# ISP6P5_NSF3V register map
Vendor: Texas Instruments
Peripheral module from a debugger description file (folder DRA74xP_75xP_76xP_77xP).
Registers are 32-bit, access per field, reset 0x0 unless marked. A register's access mark holds for its fields unless they carry their own. Offsets are as the file gives them; lines under a group give offsets from that group; [hi:lo] are bit positions; {n}, {i} and the like mark numbered series; 'fields as' and 'values as' point back to an identical list; <NAME> marks a mode.

## ISP6P5_NSF3V
0x00 NSF3V_SYSCONFIG — OCP interface
  [0] SOFTRESET rw — Software reset Read 0: Reset done, no pending action Write 0: No action Write 1: Initiate software reset Read 1: Reset (software or other) ongoing
0x08 NSF3V_CTRL — Control
  [0] EN rw — Enable NSF3V operation, for either single frame or video, depending onNSF3V_CFG.ONESHOT. Writing 0 stops NSF3V operation and puts it in idle mode.
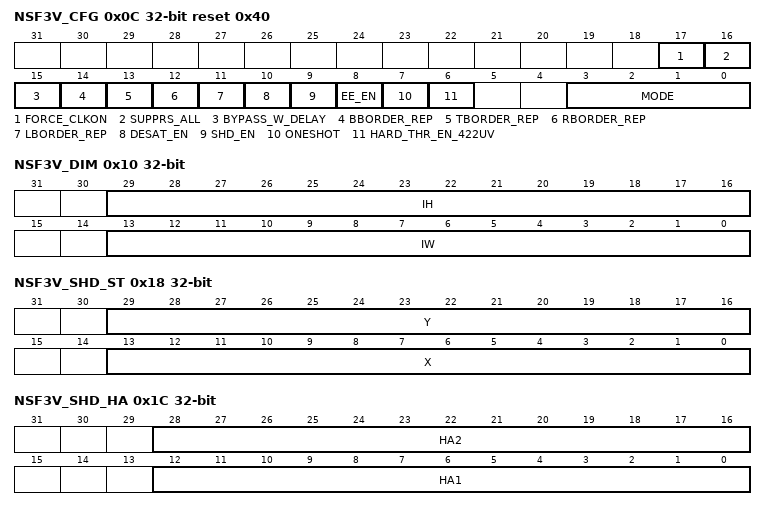
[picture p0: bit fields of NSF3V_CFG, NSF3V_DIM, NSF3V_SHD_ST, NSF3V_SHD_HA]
0x0C NSF3V_CFG reset 0x40 — Configuration
  [17] FORCE_CLKON rw — Force clock to be on, disabling clock autogating.
  [16] SUPPRS_ALL rw — Suppress all subband signals (debug mode). In normal operation, this should be set 0.
  [15] BYPASS_W_DELAY rw — Bypass all processing, so that output = input, but maintain the same latency
  [14] BBORDER_REP rw — Replicate top border to not lose 7 lines per color on the bottom.
  [13] TBORDER_REP rw — Replicate top border to not lose 7 lines per color on the top.
  [12] RBORDER_REP rw — Replicate right border to not lose 8 data points per color on the right.
  [11] LBORDER_REP rw — Replicate left border to not lose 8 data points per color on the left.
  [10] DESAT_EN rw — enable chroma desaturation
  [9] SHD_EN rw — enable shading gain
  [8] EE_EN rw — enable edge enhancement
  [7] ONESHOT rw — Video (continuous operation) or one shot (single-frame): 0 = video 1 = one-shot
  [6] HARD_THR_EN_422UV rw — Hard thresholding enable, applicable to YUV422 (normal and interleaved) UV path
  [3:0] MODE rw — Mode of operation: 0 = Bayer 1 = Bayer interleaved 2x2 2 = Bayer interleaved 3x3 3 = YUV422 4 = YUV420 Y plane 5 = YuV420 UV plane 6 = YUV422 interleaved 7 = YUV420 Y interleaved 8 = YUV420 UV interleaved 9 ~ 15 = reserved
0x10 NSF3V_DIM — Image block dimension
  [29:16] IH rw — Image height, in lines. For Bayer, YUV422, and YUV420_Y, this is same as vertical resolution in pixels. For YUV420_UV, image height is half of vertical resolution in pixels.
  [13:0] IW rw — Image width, in pixels. For Bayer and YUV420_Y, YUV420_UV, this is the same as number of data points horizontally. For YUV422, this is half of number of data points horizontally.
0x14 NSF3V_VPOUT_CTRL reset 0xFFFF — Video port output control
  [15:0] PCLK rw — Video port output data rate, indicate that VPOUT EN signal should be sent functional clock * PCLK / 65536. Must be 0, = 65535
0x18 NSF3V_SHD_ST — Shading gain starting coordinate
  [29:16] Y rw — shading gain starting Y coordinate
  [13:0] X rw — shading gain starting X coordinate
0x1C NSF3V_SHD_HA — Shading gain HA1/HA2
  [28:16] HA2 rw — shading gain HA2 coefficient
  [12:0] HA1 rw — shading gain HA1 coefficient
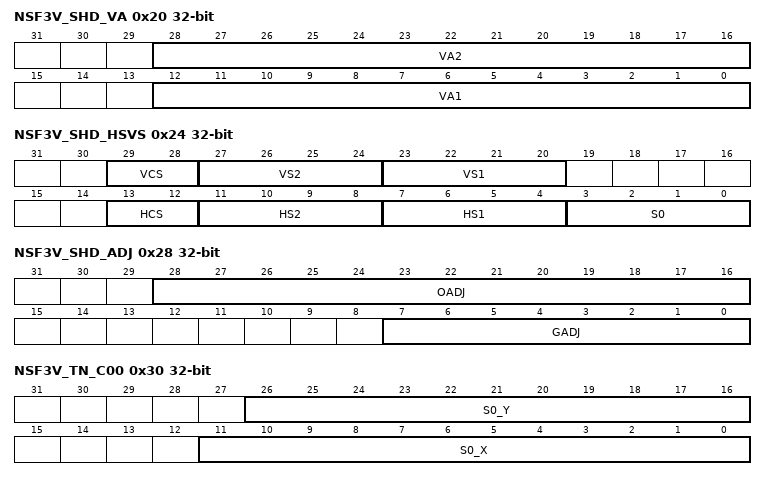
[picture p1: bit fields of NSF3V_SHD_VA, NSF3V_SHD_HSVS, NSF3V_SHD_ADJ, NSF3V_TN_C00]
0x20 NSF3V_SHD_VA — Shading gain VA1/VA2
  [28:16] VA2 rw — shading gain VA2 coefficient
  [12:0] VA1 rw — shading gain VA1 coefficient
0x24 NSF3V_SHD_HSVS — Shading gain shift counts
  [29:28] VCS rw — Vshading gain VCS shift count, only 1 or 2 allowed
  [27:24] VS2 rw — shading gain VS2 shift count
  [23:20] VS1 rw — shading gain VS1 bit count
  [13:12] HCS rw — shading gain HCS shift count, only 1 or 2 allowed
  [11:8] HS2 rw — shading gain HS2 bit count
  [7:4] HS1 rw — shading gain HS1 shift count
  [3:0] S0 rw — shading gain S0 shift count
0x28 NSF3V_SHD_ADJ — Shading gain adjustment
  [28:16] OADJ rw — shading gain offset adjustment
  [7:0] GADJ rw — shading gain gain adjustment, unsigned
0x2C NSF3V_SHD_MAXG — Max shading gain
  [8:0] MAXG rw
0x30 NSF3V_TN_C00 — Color 0 noise threshold
  [26:16] S0_Y rw — segment 0 Y coordinate, U11
  [11:0] S0_X ro — segment 0 X coordinate, U12, fixed to 0 (read-only)
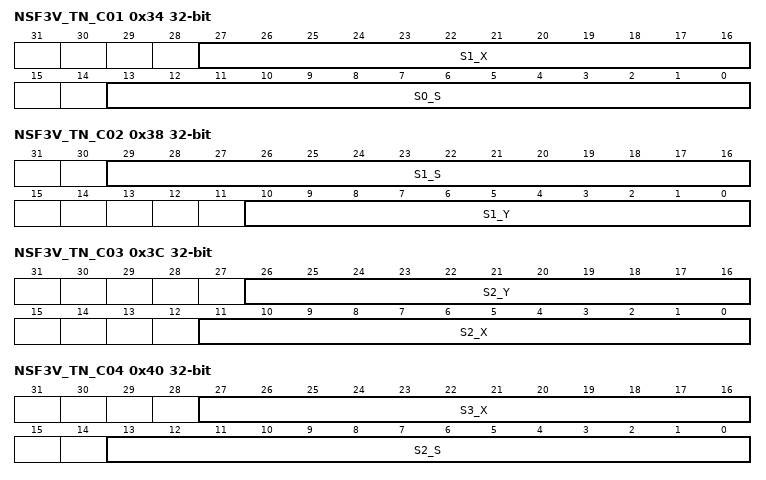
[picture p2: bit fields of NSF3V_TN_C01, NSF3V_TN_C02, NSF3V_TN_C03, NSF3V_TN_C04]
0x34 NSF3V_TN_C01 — Color 0 noise threshold
  [27:16] S1_X rw — segment 1 X coordinate, U12
  [13:0] S0_S rw — segment 0 slope, S3.11
0x38 NSF3V_TN_C02 — Color 0 noise threshold
  [29:16] S1_S rw — segment 1 slope, S3.11
  [10:0] S1_Y rw — segment 1 Y coordinate, U11
0x3C NSF3V_TN_C03 — Color 0 noise threshold
  [26:16] S2_Y rw — segment 2 Y coordinate, U11
  [11:0] S2_X rw — segment 2 X coordinate, U12
0x40 NSF3V_TN_C04 — Color 0 noise threshold
  [27:16] S3_X rw — segment 3 X coordinate, U12
  [13:0] S2_S rw — segment 2 slope, S3.11
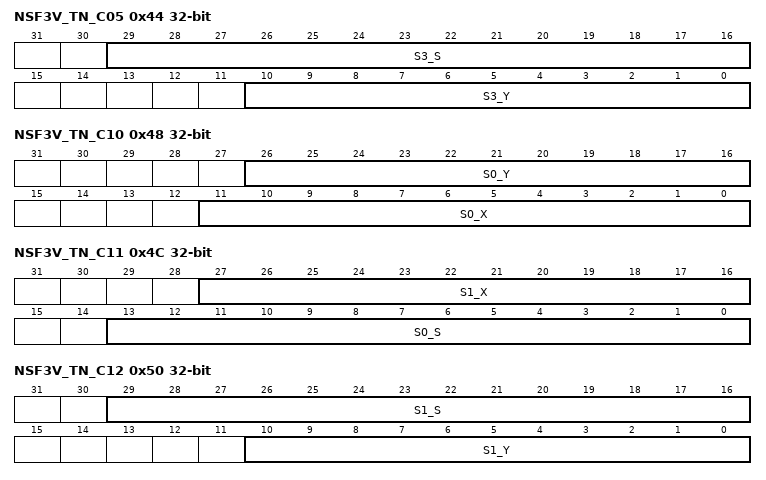
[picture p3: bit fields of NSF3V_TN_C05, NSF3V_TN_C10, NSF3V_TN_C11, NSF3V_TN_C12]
0x44 NSF3V_TN_C05 — Color 0 noise threshold
  [29:16] S3_S rw — segment 3 slope, S3.11
  [10:0] S3_Y rw — segment 3 Y coordinate, U11
0x48 NSF3V_TN_C10 — Color 1 noise threshold
  fields as NSF3V_TN_C00
0x4C NSF3V_TN_C11 — Color 1 noise threshold
  fields as NSF3V_TN_C01
0x50 NSF3V_TN_C12 — Color 1 noise threshold
  fields as NSF3V_TN_C02
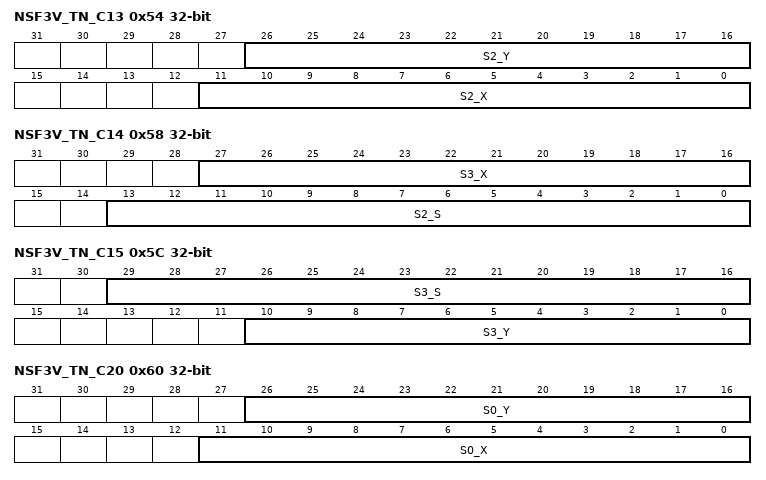
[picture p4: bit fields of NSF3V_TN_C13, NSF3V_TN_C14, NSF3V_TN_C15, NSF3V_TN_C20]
0x54 NSF3V_TN_C13 — Color 1 noise threshold
  fields as NSF3V_TN_C03
0x58 NSF3V_TN_C14 — Color 1 noise threshold
  fields as NSF3V_TN_C04
0x5C NSF3V_TN_C15 — Color 1 noise threshold
  fields as NSF3V_TN_C05
0x60 NSF3V_TN_C20 — Color 2 noise threshold
  fields as NSF3V_TN_C00
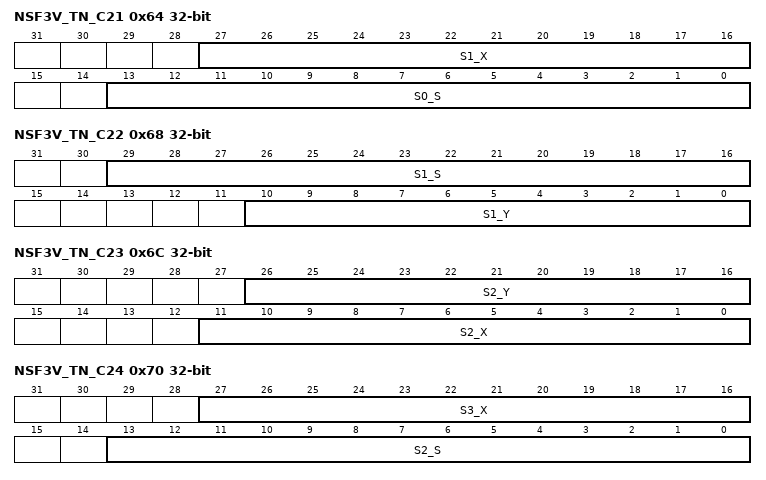
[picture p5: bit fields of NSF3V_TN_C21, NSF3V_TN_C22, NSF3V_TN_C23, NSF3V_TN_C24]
0x64 NSF3V_TN_C21 — Color 2 noise threshold
  fields as NSF3V_TN_C01
0x68 NSF3V_TN_C22 — Color 2 noise threshold
  fields as NSF3V_TN_C02
0x6C NSF3V_TN_C23 — Color 2 noise threshold
  fields as NSF3V_TN_C03
0x70 NSF3V_TN_C24 — Color 2 noise threshold
  fields as NSF3V_TN_C04
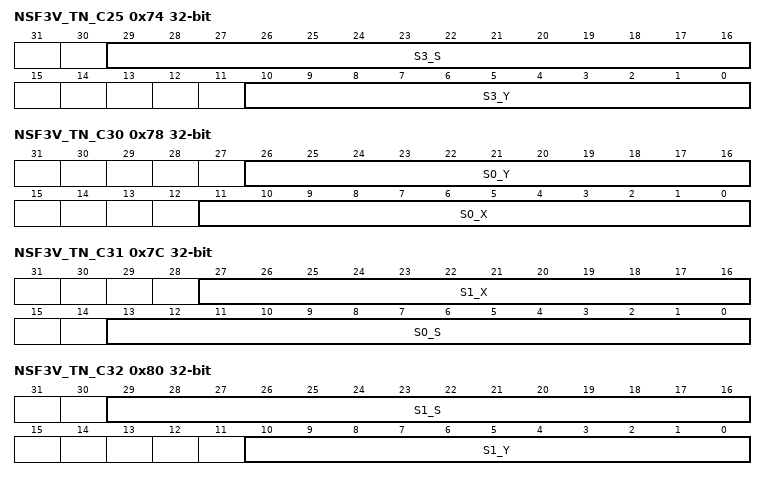
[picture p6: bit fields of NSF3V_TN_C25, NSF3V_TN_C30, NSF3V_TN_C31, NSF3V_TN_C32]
0x74 NSF3V_TN_C25 — Color 2 noise threshold
  fields as NSF3V_TN_C05
0x78 NSF3V_TN_C30 — Color 3 noise threshold
  fields as NSF3V_TN_C00
0x7C NSF3V_TN_C31 — Color 3 noise threshold
  fields as NSF3V_TN_C01
0x80 NSF3V_TN_C32 — Color 3 noise threshold
  fields as NSF3V_TN_C02
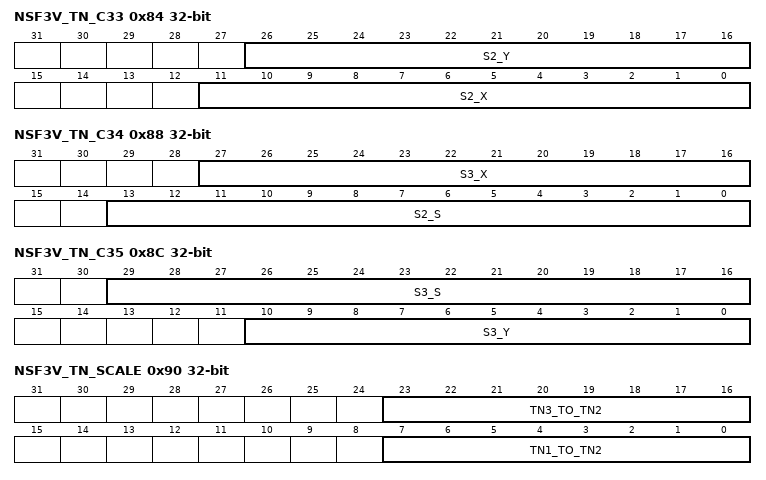
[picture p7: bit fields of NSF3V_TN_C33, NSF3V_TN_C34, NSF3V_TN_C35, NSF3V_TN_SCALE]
0x84 NSF3V_TN_C33 — Color 3 noise threshold
  fields as NSF3V_TN_C03
0x88 NSF3V_TN_C34 — Color 3 noise threshold
  fields as NSF3V_TN_C04
0x8C NSF3V_TN_C35 — Color 3 noise threshold
  fields as NSF3V_TN_C05
0x90 NSF3V_TN_SCALE
  [23:16] TN3_TO_TN2 rw — Scaling factor to get TN3, noise threshold for level 3 subbands, U3.5.
  [7:0] TN1_TO_TN2 rw — Scaling factor to get TN1, noise threshold for level 1 subbands, U3.5.
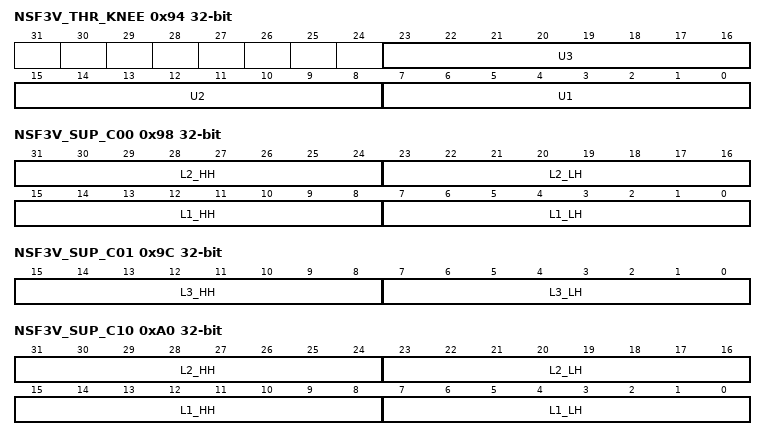
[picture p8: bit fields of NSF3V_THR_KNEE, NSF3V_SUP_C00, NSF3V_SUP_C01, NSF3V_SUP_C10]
0x94 NSF3V_THR_KNEE — Thresholding knee points
  [23:16] U3 rw — Knee point u3, above which ee = ee_max. U2.6 representation, 64 = u2 u3 = 255.
  [15:8] U2 rw — Knee point u2, below which ee = 0. Above u2, ee increases linearly to ee_max at u = u3. U2.6 representation, 64 = u2 u3 = 255.
  [7:0] U1 rw — Knee point u1, below which suppression = suppression_max. Above u1, suppression decreases linearly to 0 at u = 1.0. U2.6 representation, between 0 and 63.
0x98 NSF3V_SUP_C00 rw — Color 0 suppression max
  [31:24] L2_HH — Level 2 HH subband suppression_max, U1.7.
  [23:16] L2_LH — Level 2 LH and HL subband suppression_max, U1.7.
  [15:8] L1_HH — Level 1 HH subband suppression_max, U1.7.
  [7:0] L1_LH — Level 1 LH and HL subband suppression_max, U1.7.
0x9C NSF3V_SUP_C01 — Color 0 suppression max
  [15:8] L3_HH rw — Level 3 HH subband suppression_max, U1.7.
  [7:0] L3_LH rw — Level 3 LH and HL subband suppression_max, U1.7.
0xA0 NSF3V_SUP_C10 rw — Color 1 suppression max
  fields as NSF3V_SUP_C00
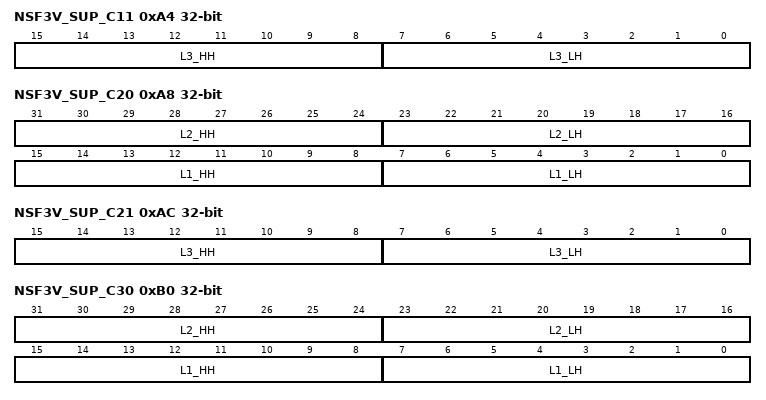
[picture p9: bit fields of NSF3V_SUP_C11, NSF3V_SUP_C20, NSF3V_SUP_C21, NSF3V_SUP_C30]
0xA4 NSF3V_SUP_C11 — Color 1 suppression max
  fields as NSF3V_SUP_C01
0xA8 NSF3V_SUP_C20 rw — Color 2 suppression max
  fields as NSF3V_SUP_C00
0xAC NSF3V_SUP_C21 — Color 2 suppression max
  fields as NSF3V_SUP_C01
0xB0 NSF3V_SUP_C30 rw — Color 3 suppression max
  fields as NSF3V_SUP_C00
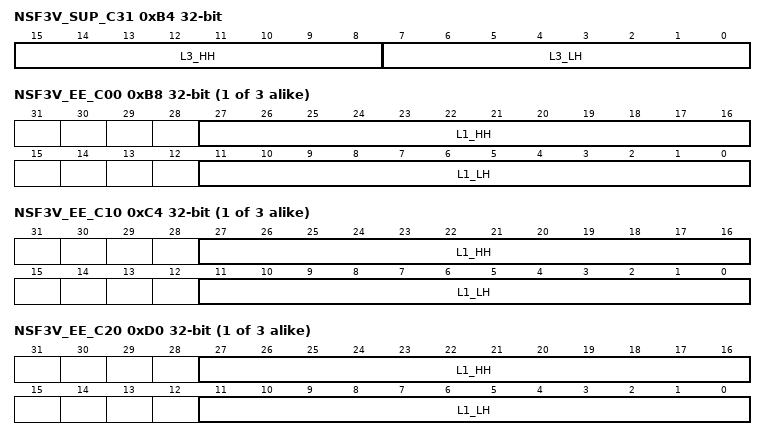
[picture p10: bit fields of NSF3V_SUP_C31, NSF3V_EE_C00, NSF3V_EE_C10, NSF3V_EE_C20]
0xB4 NSF3V_SUP_C31 — Color 3 suppression max
  fields as NSF3V_SUP_C01
{0xB8+4i} NSF3V_EE_C{i:02} (i=0..2) — Color 0 edge enhancement max
  [27:16] L{i+1}_HH rw — Level {i+1} HH suband ee_max, U10.2
  [11:0] L{i+1}_LH rw — Level {i+1} LH and HL subband ee_max, U10.2
{0x9C+4i} NSF3V_EE_C{i} (i=10..12) — Color 1 edge enhancement max
  [27:16] L{i-9}_HH rw — Level {i-9} HH suband ee_max, U10.2
  [11:0] L{i-9}_LH rw — Level {i-9} LH and HL subband ee_max, U10.2
{0x80+4i} NSF3V_EE_C{i} (i=20..22) — Color 2 edge enhancement max
  [27:16] L{i-19}_HH rw — Level {i-19} HH suband ee_max, U10.2
  [11:0] L{i-19}_LH rw — Level {i-19} LH and HL subband ee_max, U10.2
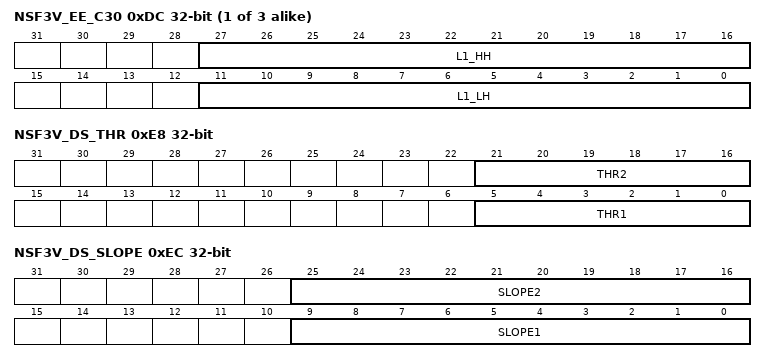
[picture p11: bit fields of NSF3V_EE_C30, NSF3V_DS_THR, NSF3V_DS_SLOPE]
{0x64+4i} NSF3V_EE_C{i} (i=30..32) — Color 3 edge enhancement max
  [27:16] L{i-29}_HH rw — Level {i-29} HH suband ee_max, U10.2
  [11:0] L{i-29}_LH rw — Level {i-29} LH and HL subband ee_max, U10.2
0xE8 NSF3V_DS_THR — Desaturation thresholds
  [21:16] THR2 rw — desaturation threshold 2, U6.0
  [5:0] THR1 rw — desaturation threhsold 1, U6.0
0xEC NSF3V_DS_SLOPE — Desaturation slopes
  [25:16] SLOPE2 rw — desaturation slope 2, U0.10
  [9:0] SLOPE1 rw — desaturation slope 1, U0.10
